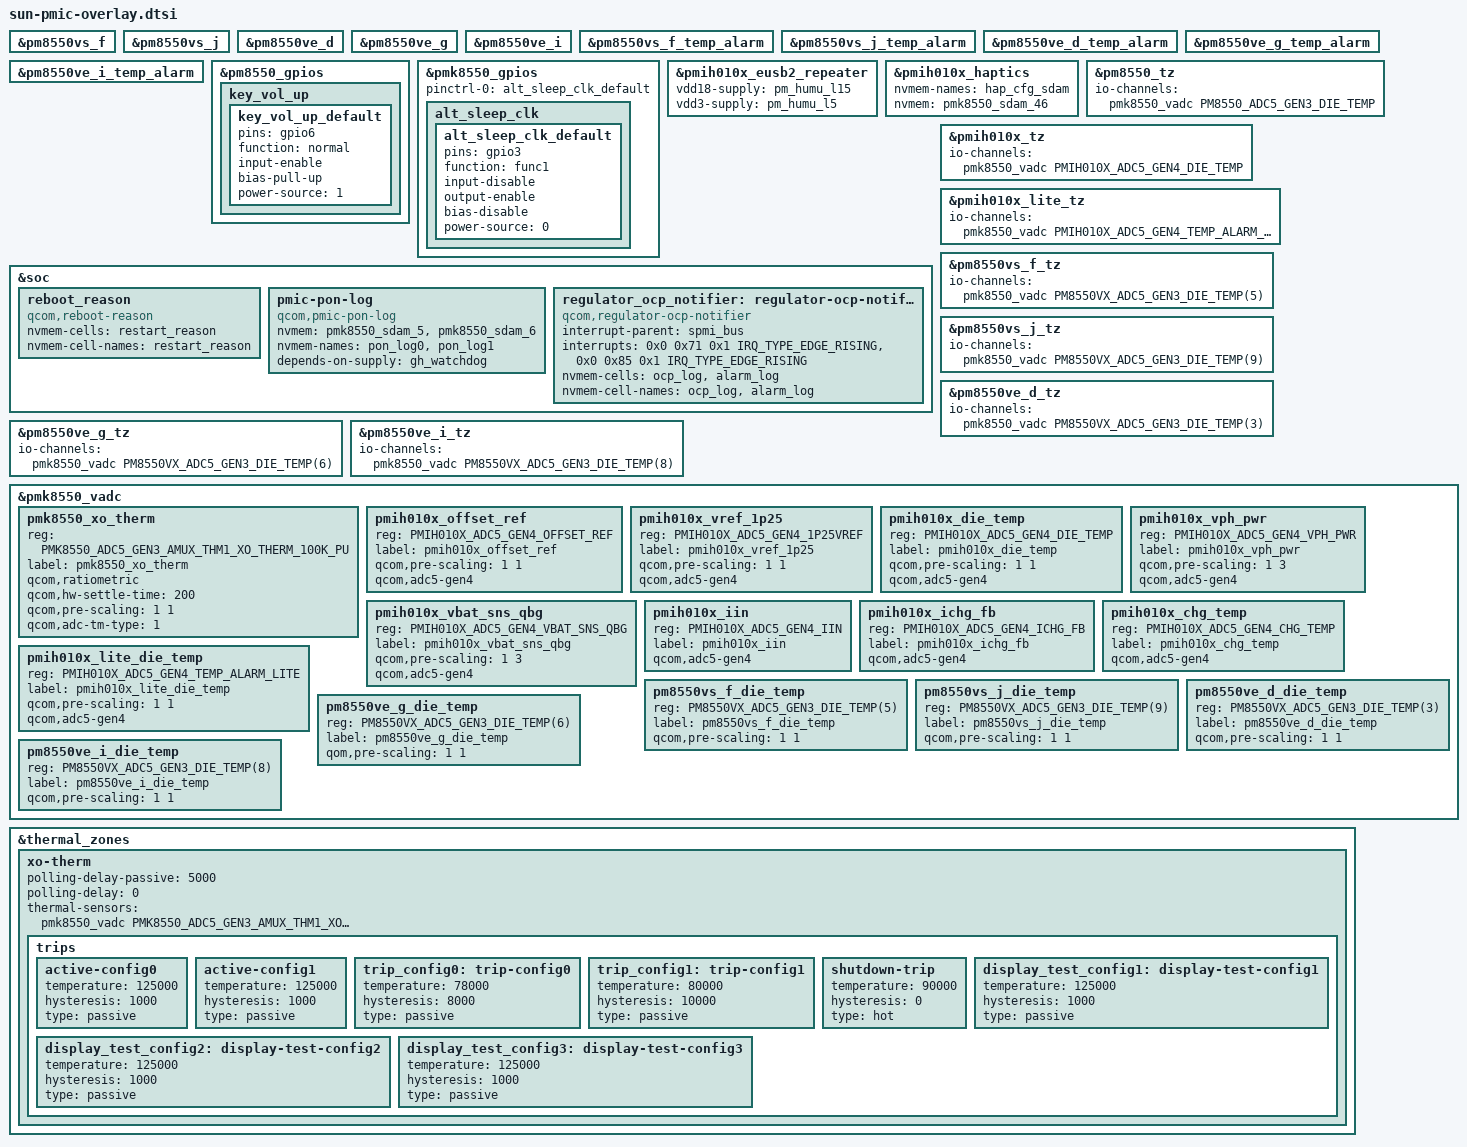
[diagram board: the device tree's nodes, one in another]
// SPDX-License-Identifier: BSD-3-Clause
/*
 * Copyright (c) 2023-2024 Qualcomm Innovation Center, Inc. All rights reserved.
 */

#include <dt-bindings/gpio/gpio.h>

#include "pm8010.dtsi"
#include "pm8550.dtsi"
#include "pm8550ve.dtsi"
#include "pm8550vs.dtsi"
#include "pmd802x.dtsi"
#include "pmih010x.dtsi"
#include "pmk8550.dtsi"
#include "pmr735d.dtsi"

&pm8550vs_f {
	status = "ok";
};

&pm8550vs_j {
	status = "ok";
};

&pm8550ve_d {
	status = "ok";
};

&pm8550ve_g {
	status = "ok";
};

&pm8550ve_i {
	status = "ok";
};

&pm8550vs_f_temp_alarm {
	status = "ok";
};

&pm8550vs_j_temp_alarm {
	status = "ok";
};

&pm8550ve_d_temp_alarm {
	status = "ok";
};

&pm8550ve_g_temp_alarm {
	status = "ok";
};

&pm8550ve_i_temp_alarm {
	status = "ok";
};

&pm8550_gpios {
	key_vol_up {
		key_vol_up_default: key_vol_up_default {
			pins = "gpio6";
			function = "normal";
			input-enable;
			bias-pull-up;
			power-source = <1>;
		};
	};
};

&pmk8550_gpios {
	pinctrl-0 = <&alt_sleep_clk_default>;
	pinctrl-names = "default";

	alt_sleep_clk {
		alt_sleep_clk_default: alt_sleep_clk_default {
			pins = "gpio3";
			function = "func1";
			input-disable;
			output-enable;
			bias-disable;
			power-source = <0>;
		};
	};
};

&pmih010x_eusb2_repeater {
	vdd18-supply = <&pm_humu_l15>;
	vdd3-supply = <&pm_humu_l5>;
};

&pmih010x_haptics {
	nvmem-names = "hap_cfg_sdam";
	nvmem = <&pmk8550_sdam_46>;
};

&soc {
	reboot_reason {
		compatible = "qcom,reboot-reason";
		nvmem-cells = <&restart_reason>;
		nvmem-cell-names = "restart_reason";
	};

	pmic-pon-log {
		compatible = "qcom,pmic-pon-log";
		nvmem = <&pmk8550_sdam_5>, <&pmk8550_sdam_6>;
		nvmem-names = "pon_log0", "pon_log1";
		depends-on-supply = <&gh_watchdog>;
	};

	regulator_ocp_notifier: regulator-ocp-notifier {
		compatible = "qcom,regulator-ocp-notifier";
		interrupt-parent = <&spmi_bus>;
		interrupts = <0x0 0x71 0x1 IRQ_TYPE_EDGE_RISING>,
			     <0x0 0x85 0x1 IRQ_TYPE_EDGE_RISING>;
		nvmem-cells = <&ocp_log>, <&alarm_log>;
		nvmem-cell-names = "ocp_log", "alarm_log";
	};
};

&pm8550_tz {
	io-channels = <&pmk8550_vadc PM8550_ADC5_GEN3_DIE_TEMP>;
	io-channel-names = "thermal";
};

&pmih010x_tz {
	io-channels = <&pmk8550_vadc PMIH010X_ADC5_GEN4_DIE_TEMP>;
	io-channel-names = "thermal";
};

&pmih010x_lite_tz {
	io-channels = <&pmk8550_vadc PMIH010X_ADC5_GEN4_TEMP_ALARM_LITE>;
	io-channel-names = "thermal";
};

&pm8550vs_f_tz {
	io-channels = <&pmk8550_vadc PM8550VX_ADC5_GEN3_DIE_TEMP(5)>;
	io-channel-names = "thermal";
};

&pm8550vs_j_tz {
	io-channels = <&pmk8550_vadc PM8550VX_ADC5_GEN3_DIE_TEMP(9)>;
	io-channel-names = "thermal";
};

&pm8550ve_d_tz {
	io-channels = <&pmk8550_vadc PM8550VX_ADC5_GEN3_DIE_TEMP(3)>;
	io-channel-names = "thermal";
};

&pm8550ve_g_tz {
	io-channels = <&pmk8550_vadc PM8550VX_ADC5_GEN3_DIE_TEMP(6)>;
	io-channel-names = "thermal";
};

&pm8550ve_i_tz {
	io-channels = <&pmk8550_vadc PM8550VX_ADC5_GEN3_DIE_TEMP(8)>;
	io-channel-names = "thermal";
};

&pmk8550_vadc {
	pmk8550_xo_therm {
		reg = <PMK8550_ADC5_GEN3_AMUX_THM1_XO_THERM_100K_PU>;
		label = "pmk8550_xo_therm";
		qcom,ratiometric;
		qcom,hw-settle-time = <200>;
		qcom,pre-scaling = <1 1>;
		qcom,adc-tm-type = <1>;
	};

	pmih010x_offset_ref {
		reg = <PMIH010X_ADC5_GEN4_OFFSET_REF>;
		label = "pmih010x_offset_ref";
		qcom,pre-scaling = <1 1>;
		qcom,adc5-gen4;
	};

	pmih010x_vref_1p25 {
		reg = <PMIH010X_ADC5_GEN4_1P25VREF>;
		label = "pmih010x_vref_1p25";
		qcom,pre-scaling = <1 1>;
		qcom,adc5-gen4;
	};

	pmih010x_die_temp {
		reg = <PMIH010X_ADC5_GEN4_DIE_TEMP>;
		label = "pmih010x_die_temp";
		qcom,pre-scaling = <1 1>;
		qcom,adc5-gen4;
	};

	pmih010x_vph_pwr {
		reg = <PMIH010X_ADC5_GEN4_VPH_PWR>;
		label = "pmih010x_vph_pwr";
		qcom,pre-scaling = <1 3>;
		qcom,adc5-gen4;
	};

	pmih010x_vbat_sns_qbg {
		reg = <PMIH010X_ADC5_GEN4_VBAT_SNS_QBG>;
		label = "pmih010x_vbat_sns_qbg";
		qcom,pre-scaling = <1 3>;
		qcom,adc5-gen4;
	};

	pmih010x_iin {
		reg = <PMIH010X_ADC5_GEN4_IIN>;
		label = "pmih010x_iin";
		qcom,adc5-gen4;
	};

	pmih010x_ichg_fb {
		reg = <PMIH010X_ADC5_GEN4_ICHG_FB>;
		label = "pmih010x_ichg_fb";
		qcom,adc5-gen4;
	};

	pmih010x_chg_temp {
		reg = <PMIH010X_ADC5_GEN4_CHG_TEMP>;
		label = "pmih010x_chg_temp";
		qcom,adc5-gen4;
	};

	pmih010x_lite_die_temp {
		reg = <PMIH010X_ADC5_GEN4_TEMP_ALARM_LITE>;
		label = "pmih010x_lite_die_temp";
		qcom,pre-scaling = <1 1>;
		qcom,adc5-gen4;
	};

	pm8550vs_f_die_temp {
		reg = <PM8550VX_ADC5_GEN3_DIE_TEMP(5)>;
		label = "pm8550vs_f_die_temp";
		qcom,pre-scaling = <1 1>;
	};

	pm8550vs_j_die_temp {
		reg = <PM8550VX_ADC5_GEN3_DIE_TEMP(9)>;
		label = "pm8550vs_j_die_temp";
		qcom,pre-scaling = <1 1>;
	};

	pm8550ve_d_die_temp {
		reg = <PM8550VX_ADC5_GEN3_DIE_TEMP(3)>;
		label = "pm8550ve_d_die_temp";
		qcom,pre-scaling = <1 1>;
	};

	pm8550ve_g_die_temp {
		reg = <PM8550VX_ADC5_GEN3_DIE_TEMP(6)>;
		label = "pm8550ve_g_die_temp";
		qom,pre-scaling = <1 1>;
	};

	pm8550ve_i_die_temp {
		reg = <PM8550VX_ADC5_GEN3_DIE_TEMP(8)>;
		label = "pm8550ve_i_die_temp";
		qcom,pre-scaling = <1 1>;
	};
};

&thermal_zones {
	xo-therm {
		polling-delay-passive = <5000>;
		polling-delay = <0>;
		thermal-sensors = <&pmk8550_vadc PMK8550_ADC5_GEN3_AMUX_THM1_XO_THERM_100K_PU>;
		trips {
			active-config0 {
				temperature = <125000>;
				hysteresis = <1000>;
				type = "passive";
			};

			active-config1 {
				temperature = <125000>;
				hysteresis = <1000>;
				type = "passive";
			};

			trip_config0: trip-config0 {
				temperature = <78000>;
				hysteresis = <8000>;
				type = "passive";
			};

			trip_config1: trip-config1 {
				temperature = <80000>;
				hysteresis = <10000>;
				type = "passive";
			};

			shutdown-trip {
				temperature = <90000>;
				hysteresis = <0>;
				type = "hot";
			};

			display_test_config1: display-test-config1 {
				temperature = <125000>;
				hysteresis = <1000>;
				type = "passive";
			};

			display_test_config2: display-test-config2 {
				temperature = <125000>;
				hysteresis = <1000>;
				type = "passive";
			};

			display_test_config3: display-test-config3 {
				temperature = <125000>;
				hysteresis = <1000>;
				type = "passive";
			};
		};
	};
};
